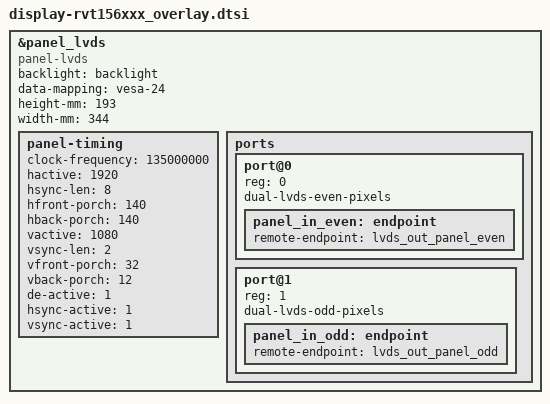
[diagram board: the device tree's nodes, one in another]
// SPDX-License-Identifier: GPL-2.0-or-later OR MIT
/*
 * Copyright 2023 Toradex
 */

// RVT156XXX-B DSI display (15.6 inch) with a resolution of 1920x1080 pixel.

&panel_lvds {
	compatible = "panel-lvds";
	backlight = <&backlight>;
	data-mapping = "vesa-24";
	height-mm = <193>;
	width-mm = <344>;
	status = "okay";

	panel-timing {
		clock-frequency = <135000000>;
		hactive = <1920>;
		hsync-len = <8>;
		hfront-porch = <140>;
		hback-porch = <140>;

		vactive = <1080>;
		vsync-len = <2>;
		vfront-porch = <32>;
		vback-porch = <12>;

		de-active = <1>;
		hsync-active = <1>;
		vsync-active = <1>;
	};

	ports {
		#address-cells = <1>;
		#size-cells = <0>;

		port@0 {
			reg = <0>;
			dual-lvds-even-pixels;
			panel_in_even: endpoint {
				remote-endpoint = <&lvds_out_panel_even>;
			};
		};

		port@1 {
			reg = <1>;
			dual-lvds-odd-pixels;
			panel_in_odd: endpoint {
				remote-endpoint = <&lvds_out_panel_odd>;
			};
		};
	};	
};
